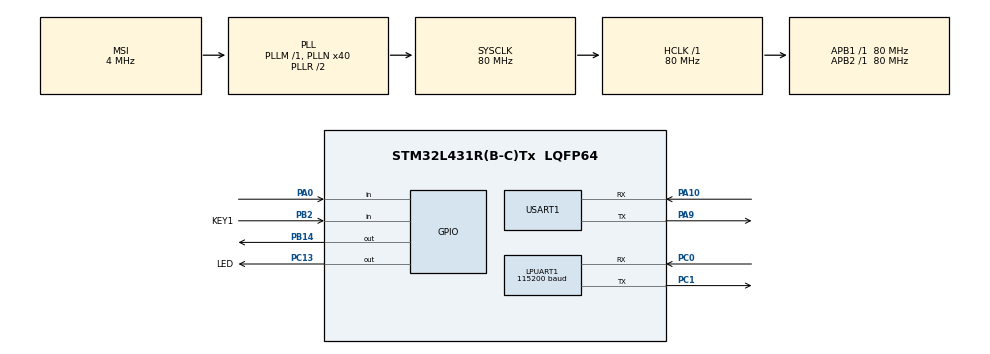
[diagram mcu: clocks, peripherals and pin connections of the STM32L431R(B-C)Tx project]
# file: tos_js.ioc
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LPUART1.BaudRate=115200
LPUART1.WordLength=UART_WORDLENGTH_8B
Mcu.Family=STM32L4
Mcu.Name=STM32L431R(B-C)Tx
Mcu.Package=LQFP64
NVIC.LPUART1_IRQn=true\:0\:0\:false\:false\:true\:true\:true
NVIC.PriorityGroup=NVIC_PRIORITYGROUP_4
PA0.Signal=GPIO_Input
PA10.Mode=Asynchronous
PA10.Signal=USART1_RX
PA9.Mode=Asynchronous
PA9.Signal=USART1_TX
PB14.PinState=GPIO_PIN_SET
PB14.Signal=GPIO_Output
PB2.GPIO_Label=KEY1
PB2.Signal=GPIO_Input
PC0.Mode=Asynchronous
PC0.Signal=LPUART1_RX
PC1.Mode=Asynchronous
PC1.Signal=LPUART1_TX
PC13.GPIO_Label=LED
PC13.PinState=GPIO_PIN_SET
PC13.Signal=GPIO_Output
PC14-OSC32_IN\ (PC14).Mode=LSE-External-Oscillator
PC14-OSC32_IN\ (PC14).Signal=RCC_OSC32_IN
PC15-OSC32_OUT\ (PC15).Mode=LSE-External-Oscillator
PC15-OSC32_OUT\ (PC15).Signal=RCC_OSC32_OUT
PH0-OSC_IN\ (PH0).Mode=HSE-External-Oscillator
PH0-OSC_IN\ (PH0).Signal=RCC_OSC_IN
PH1-OSC_OUT\ (PH1).Mode=HSE-External-Oscillator
PH1-OSC_OUT\ (PH1).Signal=RCC_OSC_OUT
ProjectManager.HeapSize=0x200
ProjectManager.StackSize=0x400
ProjectManager.TargetToolchain=Makefile
RCC.ADCFreq_Value=32000000
RCC.AHBFreq_Value=80000000
RCC.APB1Freq_Value=80000000
RCC.APB1TimFreq_Value=80000000
RCC.APB2Freq_Value=80000000
RCC.APB2TimFreq_Value=80000000
RCC.CortexFreq_Value=80000000
RCC.HCLKFreq_Value=80000000
RCC.HSE_VALUE=8000000
RCC.HSI48_VALUE=48000000
RCC.HSI_VALUE=16000000
RCC.MSI_VALUE=4000000
RCC.PLLN=40
RCC.PLLSAI1N=16
RCC.SYSCLKFreq_VALUE=80000000
RCC.SYSCLKSource=RCC_SYSCLKSOURCE_PLLCLK
RCC.VCOOutputFreq_Value=160000000
USART1.Parity=PARITY_NONE
USART1.VirtualMode-Asynchronous=VM_ASYNC
board=custom

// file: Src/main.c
/* USER CODE BEGIN Header */
/**
  ******************************************************************************
  * @file           : main.c
  * @brief          : Main program body
  ******************************************************************************
  * @attention
  *
  * <h2><center>&copy; Copyright (c) 2021 STMicroelectronics.
  * All rights reserved.</center></h2>
  *
  * This software component is licensed by ST under BSD 3-Clause license,
  * the "License"; You may not use this file except in compliance with the
  * License. You may obtain a copy of the License at:
  *                        opensource.org/licenses/BSD-3-Clause
  *
  ******************************************************************************
  */
/* USER CODE END Header */
#include "main.h"
#include "usart.h"
#include "gpio.h"

/* USER CODE BEGIN Includes */
#include "tos_k.h"
#include "util.h"
#include "task.h"
#include "js.h"
#include "tos_k.h"
/* USER CODE END Includes */

void SystemClock_Config(void);

int main(void)
{

  /* MCU Configuration--------------------------------------------------------*/

  /* Reset of all peripherals, Initializes the Flash interface and the Systick. */
  HAL_Init();

  /* Configure the system clock */
  SystemClock_Config();

  /* Initialize all configured peripherals */
  MX_GPIO_Init();
  MX_USART1_UART_Init();
  MX_LPUART1_UART_Init();
  /* USER CODE BEGIN 2 */
  tos_knl_init();
  tos_task_create_dyn(&k_wifi_connect, "wifi_connect", task_wifi_connect, NULL,
                      4, TASK_SIZE_WIFI_CONNECT, 0);
  tos_knl_start();
  /* USER CODE END 2 */

  /* Infinite loop */
  while (1)
  {

  }
}

void SystemClock_Config(void)
{
  RCC_OscInitTypeDef RCC_OscInitStruct = {0};
  RCC_ClkInitTypeDef RCC_ClkInitStruct = {0};
  RCC_PeriphCLKInitTypeDef PeriphClkInit = {0};

  /** Configure LSE Drive Capability
  */
  HAL_PWR_EnableBkUpAccess();
  __HAL_RCC_LSEDRIVE_CONFIG(RCC_LSEDRIVE_LOW);
  /** Initializes the RCC Oscillators according to the specified parameters
  * in the RCC_OscInitTypeDef structure.
  */
  RCC_OscInitStruct.OscillatorType = RCC_OSCILLATORTYPE_LSE|RCC_OSCILLATORTYPE_MSI;
  RCC_OscInitStruct.LSEState = RCC_LSE_ON;
  RCC_OscInitStruct.MSIState = RCC_MSI_ON;
  RCC_OscInitStruct.MSICalibrationValue = 0;
  RCC_OscInitStruct.MSIClockRange = RCC_MSIRANGE_6;
  RCC_OscInitStruct.PLL.PLLState = RCC_PLL_ON;
  RCC_OscInitStruct.PLL.PLLSource = RCC_PLLSOURCE_MSI;
  RCC_OscInitStruct.PLL.PLLM = 1;
  RCC_OscInitStruct.PLL.PLLN = 40;
  RCC_OscInitStruct.PLL.PLLP = RCC_PLLP_DIV7;
  RCC_OscInitStruct.PLL.PLLQ = RCC_PLLQ_DIV2;
  RCC_OscInitStruct.PLL.PLLR = RCC_PLLR_DIV2;
  if (HAL_RCC_OscConfig(&RCC_OscInitStruct) != HAL_OK)
  {
    Error_Handler();
  }
  /** Initializes the CPU, AHB and APB buses clocks
  */
  RCC_ClkInitStruct.ClockType = RCC_CLOCKTYPE_HCLK|RCC_CLOCKTYPE_SYSCLK
                              |RCC_CLOCKTYPE_PCLK1|RCC_CLOCKTYPE_PCLK2;
  RCC_ClkInitStruct.SYSCLKSource = RCC_SYSCLKSOURCE_PLLCLK;
  RCC_ClkInitStruct.AHBCLKDivider = RCC_SYSCLK_DIV1;
  RCC_ClkInitStruct.APB1CLKDivider = RCC_HCLK_DIV1;
  RCC_ClkInitStruct.APB2CLKDivider = RCC_HCLK_DIV1;

  if (HAL_RCC_ClockConfig(&RCC_ClkInitStruct, FLASH_LATENCY_4) != HAL_OK)
  {
    Error_Handler();
  }
  PeriphClkInit.PeriphClockSelection = RCC_PERIPHCLK_USART1|RCC_PERIPHCLK_LPUART1;
  PeriphClkInit.Usart1ClockSelection = RCC_USART1CLKSOURCE_PCLK2;
  PeriphClkInit.Lpuart1ClockSelection = RCC_LPUART1CLKSOURCE_PCLK1;
  if (HAL_RCCEx_PeriphCLKConfig(&PeriphClkInit) != HAL_OK)
  {
    Error_Handler();
  }
  /** Configure the main internal regulator output voltage
  */
  if (HAL_PWREx_ControlVoltageScaling(PWR_REGULATOR_VOLTAGE_SCALE1) != HAL_OK)
  {
    Error_Handler();
  }
  /** Enable MSI Auto calibration
  */
  HAL_RCCEx_EnableMSIPLLMode();
}

void Error_Handler(void)
{
  __disable_irq();
  while (1)
  {
  }
}

/************************ (C) COPYRIGHT STMicroelectronics *****END OF FILE****/
